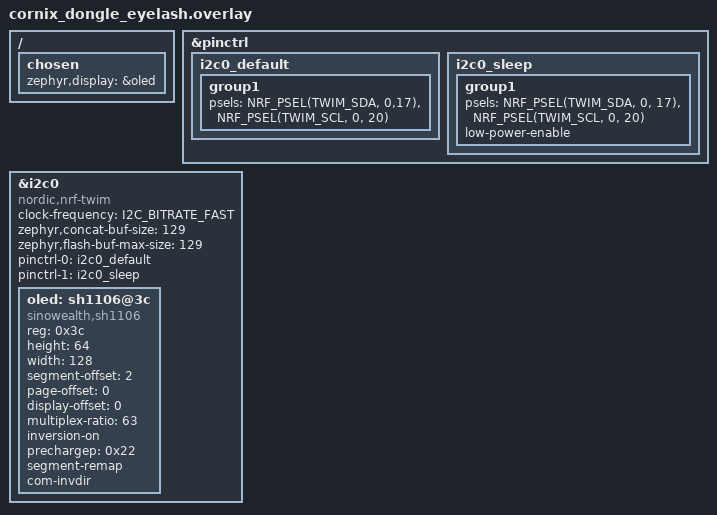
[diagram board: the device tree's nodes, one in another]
#include <dt-bindings/zmk/matrix_transform.h>
#include <zephyr/dt-bindings/i2c/i2c.h>

/{
    chosen {
        zephyr,display = &oled;
    };
};
// vim: set ft=dts :
&pinctrl {
    i2c0_default: i2c0_default {
        group1 {
            psels = <NRF_PSEL(TWIM_SDA, 0,17)>,
                <NRF_PSEL(TWIM_SCL, 0, 20)>;
        };
    };

    i2c0_sleep: i2c0_sleep {
        group1 {
            psels = <NRF_PSEL(TWIM_SDA, 0, 17)>,
                <NRF_PSEL(TWIM_SCL, 0, 20)>;
            low-power-enable;
        };
    };
};


&i2c0 {
	status = "okay";
    compatible = "nordic,nrf-twim";
    clock-frequency = <I2C_BITRATE_FAST>;
    /* SH1106 writes one 128-byte page plus its I2C control byte at a time.
     * Keep the fragments together without an intervening repeated start.
     * Zephyr shares one buffer for concatenation and flash-to-RAM copies. */
    zephyr,concat-buf-size = <129>;
    zephyr,flash-buf-max-size = <129>;
    pinctrl-0 = <&i2c0_default>;
    pinctrl-1 = <&i2c0_sleep>;
    pinctrl-names = "default", "sleep";
	oled: sh1106@3c {
        compatible = "sinowealth,sh1106";
        reg = <0x3c>;
        height = <64>;

        // old lvgl
        //width = <129>;
        //segment-offset = <1>;

        //lvgl 9.x
        width = <128>;
        segment-offset = <2>;

        page-offset = <0>;
        display-offset = <0>;
        multiplex-ratio = <63>;
        inversion-on;
        prechargep = <0x22>;

        // comment to rotate 180
        segment-remap;
        com-invdir;
	};
};

//vim: set ft=dts:
